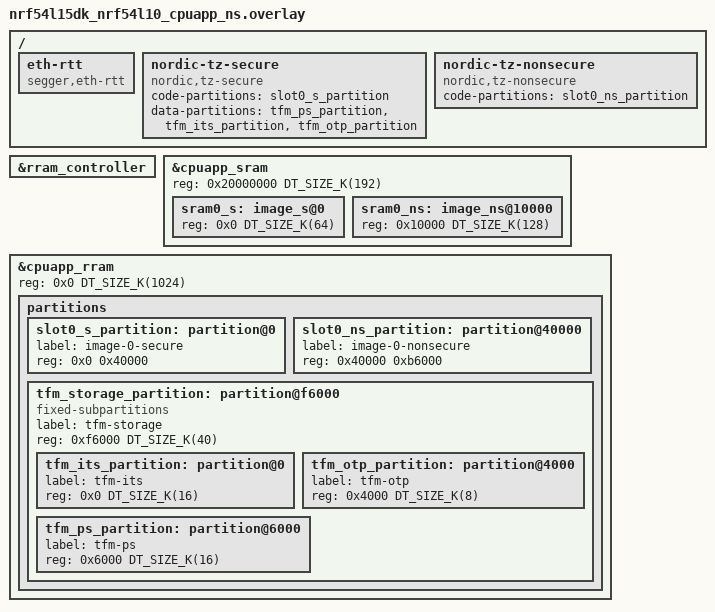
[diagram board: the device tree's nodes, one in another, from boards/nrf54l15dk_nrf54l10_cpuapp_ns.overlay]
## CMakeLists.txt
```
#
# Copyright (c) 2021 Nordic Semiconductor ASA
#
# SPDX-License-Identifier: LicenseRef-Nordic-5-Clause
#

cmake_minimum_required(VERSION 3.20.0)

find_package(Zephyr REQUIRED HINTS $ENV{ZEPHYR_BASE})

project(psa_tls_sample)

zephyr_include_directories(src ${COMMON_DIR})
target_include_directories(app PUBLIC ./include)
target_sources(app PRIVATE src/main.c
                           src/psa_tls_common.c)

if(CONFIG_BUILD_WITH_TFM)
  set(tls_src_path "non-secure")
else()
  set(tls_src_path "secure")
endif()

if(CONFIG_SAMPLE_PSA_TLS_TYPE_SERVER)
  target_sources(app PRIVATE src/${tls_src_path}/psa_tls_credentials_server.c)
  if(CONFIG_NET_SOCKETS_ENABLE_DTLS)
    target_sources(app PRIVATE src/psa_dtls_functions_server.c)
  else()
    target_sources(app PRIVATE src/psa_tls_functions_server.c)
  endif()
else()
  target_sources(app PRIVATE src/${tls_src_path}/psa_tls_credentials_client.c)
  if(CONFIG_NET_SOCKETS_ENABLE_DTLS)
    target_sources(app PRIVATE src/psa_dtls_functions_client.c)
  else()
    target_sources(app PRIVATE src/psa_tls_functions_client.c)
  endif()
endif()

set(gen_dir ${ZEPHYR_BINARY_DIR}/include/generated/)

if(CONFIG_SAMPLE_PSA_TLS_CERTIFICATE_TYPE_ECDSA)
  set(ctype "ec")
  if(CONFIG_PSA_WANT_ECC_SECP_R1_384)
    set(variant "-secp384r1")
  else()
    set(variant "-secp256r1")
  endif()
else()
  set(ctype "rsa")
  # This sample is configured to use RSA pkcs1v1.5 certificates for TLS 1.2,
  # and RSA-PSS certificates for TLS 1.3.
  if(CONFIG_MBEDTLS_SSL_PROTO_TLS1_3 AND CONFIG_PSA_WANT_ALG_RSA_PSS)
    set(variant "-pss")
  else()
    set(variant "-pkcs1v15")
  endif()
endif()

foreach(inc_file
  root-cert
  server-cert
  server-cert-key
)
  set(modified_inc_file "${ctype}-${inc_file}${variant}.der")
  generate_inc_file_for_target(
    app
    certs/${modified_inc_file}
    ${gen_dir}/${inc_file}.der.inc
  )
endforeach()
```

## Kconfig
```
#
# Copyright (c) 2021 Nordic Semiconductor
#
# SPDX-License-Identifier: LicenseRef-Nordic-5-Clause
#

source "Kconfig.zephyr"

menu "PSA TLS sample"

choice SAMPLE_PSA_TLS_CERTIFICATE_TYPE
	prompt "Certificate type"
	default SAMPLE_PSA_TLS_CERTIFICATE_TYPE_ECDSA
	help
	  Select the certificate type to use in the PSA TLS sample.

config SAMPLE_PSA_TLS_CERTIFICATE_TYPE_RSA
	bool "RSA certificate for the PSA TLS sample"
	help
	  Enable RSA certificates when testing ciphers that supports RSA for authentication.

config SAMPLE_PSA_TLS_CERTIFICATE_TYPE_ECDSA
	bool "ECDSA certificate for the PSA TLS sample"
	help
	  Enable ECDSA certificates when testing ciphers that supports ECDSA for authentication.

endchoice

choice SAMPLE_PSA_TLS_TYPE
	prompt "Server or client selection"
	default SAMPLE_PSA_TLS_TYPE_SERVER

config SAMPLE_PSA_TLS_TYPE_SERVER
	bool "Server functionality for the PSA TLS sample"
	help
	  When acting as a server, the sample waits for a connection from the client on port 4243.
	  After the TCP connection is established, the sample waits for the "ClientHello" message
	  from the client.

config SAMPLE_PSA_TLS_TYPE_CLIENT
	bool "Client functionality for the PSA TLS sample"
	help
	  When acting as a client, the sample tries to connect to the server on port 4243.
	  After the TCP connection is established, the sample automatically initiates the TLS handshake
	  by sending the "ClientHello" message.

endchoice

config SAMPLE_PSA_TLS_SERVER_PORT
	int "Server port number for the PSA TLS sample"
	range 1 65535
	default 4243
	help
	  The server port number for the PSA_TLS sample's network connection.

endmenu
```

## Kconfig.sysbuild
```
#
# Copyright (c) 2025 Nordic Semiconductor
#
# SPDX-License-Identifier: LicenseRef-Nordic-5-Clause
#

config PARTITION_MANAGER
	default n if SOC_SERIES_NRF53

source "share/sysbuild/Kconfig"
```

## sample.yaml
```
sample:
  description: |
    This sample demonstrates performing TLS handshake as either server or client.
  name: PSA TLS sample
common:
  sysbuild: true
  tags:
    - ci_build
    - sysbuild
    - ci_samples_crypto
  harness: console
  harness_config:
    type: multi_line
    ordered: true
    regex:
      - "Initializing network"
      - "psa_tls_sample: PSA TLS app started"
      - "psa_tls_credentials.* Registering"
      - "psa_tls_sample: Registering Pre-shared key"
      - "psa_.*(tls_client|tls_server).*TLS connection"
  timeout: 15
tests:
  ################################################################################
  ## ECDSA with Cryptocell and Oberon
  ################################################################################
  sample.psa_tls.tls_server.ecdsa.cc3xx_oberon:
    extra_args:
      EXTRA_CONF_FILE="overlays/server.conf;overlays/ecdsa_secp256r1.conf;overlays/tls_1_2_ecdsa.conf;overlays/cc3xx-oberon.conf"
    platform_allow: &cc3xx_oberon_platforms
      - nrf52840dk/nrf52840
      - nrf5340dk/nrf5340/cpuapp
      - nrf5340dk/nrf5340/cpuapp/ns
      - nrf9151dk/nrf9151
      - nrf9151dk/nrf9151/ns
    integration_platforms: &nrf5340_integration_platforms
      - nrf5340dk/nrf5340/cpuapp
      - nrf5340dk/nrf5340/cpuapp/ns
    tags:
      - cc3xx_oberon
  sample.psa_tls.dtls_server_secp384r1.ecdsa.cc3xx_oberon:
    extra_args:
      EXTRA_CONF_FILE="overlays/server.conf;overlays/ecdsa_secp384r1.conf;overlays/tls_1_2_ecdsa.conf;overlays/cc3xx-oberon.conf;overlays/dtls.conf"
    platform_allow: *cc3xx_oberon_platforms
    integration_platforms: &nrf9151_integration_platforms
      - nrf9151dk/nrf9151
      - nrf9151dk/nrf9151/ns
    tags:
      - dtls
      - cc3xx_oberon
      - secp384r1
  sample.psa_tls.tls_client.ecdsa.cc3xx_oberon:
    extra_args:
      EXTRA_CONF_FILE="overlays/client.conf;overlays/ecdsa_secp256r1.conf;overlays/tls_1_2_ecdsa.conf;overlays/cc3xx-oberon.conf"
    platform_allow: *cc3xx_oberon_platforms
    integration_platforms: &nrf52840_integration_platforms
      - nrf52840dk/nrf52840
    tags:
      - cc3xx_oberon
  sample.psa_tls.dtls_client_secp384r1.ecdsa.cc3xx_oberon:
    extra_args:
      EXTRA_CONF_FILE="overlays/client.conf;overlays/ecdsa_secp384r1.conf;overlays/tls_1_2_ecdsa.conf;overlays/cc3xx-oberon.conf;overlays/dtls.conf"
    platform_allow: *cc3xx_oberon_platforms
    integration_platforms: *nrf5340_integration_platforms
    tags:
      - dtls
      - cc3xx_oberon
      - secp384r1
  sample.psa_tls.tls_1_3_server.ecdsa.cc3xx_oberon:
    extra_args:
      EXTRA_CONF_FILE="overlays/server.conf;overlays/ecdsa_secp256r1.conf;overlays/tls_1_3_ecdsa.conf;overlays/cc3xx-oberon.conf"
    platform_allow: *cc3xx_oberon_platforms
    integration_platforms: *nrf5340_integration_platforms
    tags:
      - tls_1_3
      - cc3xx_oberon
  sample.psa_tls.tls_1_3_client.ecdsa.cc3xx_oberon:
    extra_args:
      EXTRA_CONF_FILE="overlays/client.conf;overlays/ecdsa_secp256r1.conf;overlays/tls_1_3_ecdsa.conf;overlays/cc3xx-oberon.conf"
    platform_allow: *cc3xx_oberon_platforms
    integration_platforms: *nrf9151_integration_platforms
    tags:
      - tls_1_3
      - cc3xx_oberon
  ################################################################################
  ## RSA with Cryptocell and Oberon
  ################################################################################
  sample.psa_tls.tls_server.rsa.cc3xx_oberon:
    extra_args:
      EXTRA_CONF_FILE="overlays/server.conf;overlays/tls_1_2_rsa.conf;overlays/cc3xx-oberon.conf"
    platform_allow: *cc3xx_oberon_platforms
    integration_platforms: *nrf5340_integration_platforms
    tags:
      - cc3xx_oberon
  sample.psa_tls.dtls_client.rsa.cc3xx_oberon:
    extra_args:
      EXTRA_CONF_FILE="overlays/client.conf;overlays/tls_1_2_rsa.conf;overlays/cc3xx-oberon.conf;overlays/dtls.conf"
    platform_allow: *cc3xx_oberon_platforms
    integration_platforms: *nrf9151_integration_platforms
    tags:
      - dtls
      - cc3xx_oberon
  sample.psa_tls.tls_1_3_server.rsa.cc3xx_oberon:
    extra_args:
      EXTRA_CONF_FILE="overlays/server.conf;overlays/tls_1_3_rsa.conf;overlays/cc3xx-oberon.conf"
    platform_allow: *cc3xx_oberon_platforms
    integration_platforms: *nrf9151_integration_platforms
    tags:
      - tls_1_3
      - cc3xx_oberon
  sample.psa_tls.tls_1_3_client.rsa.cc3xx_oberon:
    extra_args:
      EXTRA_CONF_FILE="overlays/client.conf;overlays/tls_1_3_rsa.conf;overlays/cc3xx-oberon.conf"
    platform_allow: *cc3xx_oberon_platforms
    integration_platforms: *nrf5340_integration_platforms
    tags:
      - tls_1_3
      - cc3xx_oberon
  ################################################################################
  ## ECDSA with Cracen
  ################################################################################
  sample.psa_tls.tls_server.ecdsa.cracen:
    extra_args:
      EXTRA_CONF_FILE="overlays/server.conf;overlays/ecdsa_secp256r1.conf;overlays/tls_1_2_ecdsa.conf;overlays/cracen.conf"
    platform_allow: &cracen_platforms
      - nrf54l15dk/nrf54l15/cpuapp
      - nrf54l15dk/nrf54l15/cpuapp/ns
      - nrf54lm20dk/nrf54lm20a/cpuapp
      - nrf54lm20dk/nrf54lm20a/cpuapp/ns
      - nrf54lm20dk/nrf54lm20b/cpuapp
      - nrf54lm20dk/nrf54lm20b/cpuapp/ns
      - nrf54lv10dk/nrf54lv10a/cpuapp
      - nrf54lv10dk/nrf54lv10a/cpuapp/ns
      - nrf54lc10dk/nrf54lc10a/cpuapp
      - nrf54lc10dk/nrf54lc10a/cpuapp/ns
      - nrf54l15dk/nrf54l10/cpuapp
      - nrf54l15dk/nrf54l10/cpuapp/ns
      - nrf7120dk/nrf7120/cpuapp
      - nrf7120dk/nrf7120/cpuapp/ns
    integration_platforms: &nrf54l15_integration_platforms
      - nrf54l15dk/nrf54l15/cpuapp
      - nrf54l15dk/nrf54l15/cpuapp/ns
    tags:
      - cracen
  sample.psa_tls.dtls_server.ecdsa.cracen:
    extra_args:
      EXTRA_CONF_FILE="overlays/server.conf;overlays/ecdsa_secp256r1.conf;overlays/tls_1_2_ecdsa.conf;overlays/cracen.conf;overlays/dtls.conf"
    platform_allow: *cracen_platforms
    integration_platforms: &nrf54lm20b_integration_platforms
      - nrf54lm20dk/nrf54lm20b/cpuapp
      - nrf54lm20dk/nrf54lm20b/cpuapp/ns
    tags:
      - dtls
      - cracen
  sample.psa_tls.tls_client.ecdsa.cracen:
    extra_args:
      EXTRA_CONF_FILE="overlays/client.conf;overlays/ecdsa_secp256r1.conf;overlays/tls_1_2_ecdsa.conf;overlays/cracen.conf"
    platform_allow: *cracen_platforms
    integration_platforms: &nrf54lv10a_integration_platforms
      - nrf54lv10dk/nrf54lv10a/cpuapp
      - nrf54lv10dk/nrf54lv10a/cpuapp/ns
    tags:
      - cracen
  sample.psa_tls.dtls_client.ecdsa.cracen:
    extra_args:
      EXTRA_CONF_FILE="overlays/client.conf;overlays/ecdsa_secp256r1.conf;overlays/tls_1_2_ecdsa.conf;overlays/cracen.conf;overlays/dtls.conf"
    platform_allow: *cracen_platforms
    integration_platforms: *nrf54l15_integration_platforms
    tags:
      - dtls
      - cracen
  sample.psa_tls.tls_server_secp384r1.ecdsa.cracen:
    extra_args:
      EXTRA_CONF_FILE="overlays/server.conf;overlays/ecdsa_secp384r1.conf;overlays/tls_1_2_ecdsa.conf;overlays/cracen.conf"
    platform_allow: *cracen_platforms
    integration_platforms: *nrf54lm20b_integration_platforms
    tags:
      - cracen
      - secp384r1
  sample.psa_tls.dtls_server_secp384r1.ecdsa.cracen:
    extra_args:
      EXTRA_CONF_FILE="overlays/server.conf;overlays/ecdsa_secp384r1.conf;overlays/tls_1_2_ecdsa.conf;overlays/cracen.conf;overlays/dtls.conf"
    platform_allow: *cracen_platforms
    integration_platforms: *nrf54lv10a_integration_platforms
    tags:
      - dtls
      - cracen
      - secp384r1
  sample.psa_tls.tls_client_secp384r1.ecdsa.cracen:
    extra_args:
      EXTRA_CONF_FILE="overlays/client.conf;overlays/ecdsa_secp384r1.conf;overlays/tls_1_2_ecdsa.conf;overlays/cracen.conf"
    platform_allow: *cracen_platforms
    integration_platforms: *nrf54lm20b_integration_platforms
    tags:
      - cracen
      - secp384r1
  sample.psa_tls.dtls_client_secp384r1.ecdsa.cracen:
    extra_args:
      EXTRA_CONF_FILE="overlays/client.conf;overlays/ecdsa_secp384r1.conf;overlays/tls_1_2_ecdsa.conf;overlays/cracen.conf;overlays/dtls.conf"
    platform_allow: *cracen_platforms
    integration_platforms: *nrf54l15_integration_platforms
    tags:
      - dtls
      - cracen
      - secp384r1
  sample.psa_tls.tls_1_3_server.ecdsa.cracen:
    extra_args:
      EXTRA_CONF_FILE="overlays/server.conf;overlays/ecdsa_secp256r1.conf;overlays/tls_1_3_ecdsa.conf;overlays/cracen.conf"
    platform_allow: *cracen_platforms
    integration_platforms: *nrf54lv10a_integration_platforms
    tags:
      - tls_1_3
      - cracen
  sample.psa_tls.tls_1_3_client.ecdsa.cracen:
    extra_args:
      EXTRA_CONF_FILE="overlays/client.conf;overlays/ecdsa_secp256r1.conf;overlays/tls_1_3_ecdsa.conf;overlays/cracen.conf"
    platform_allow: *cracen_platforms
    integration_platforms: *nrf54lm20b_integration_platforms
    tags:
      - tls_1_3
      - cracen
  ################################################################################
  ## ECDSA with Cracen crypto service
  ################################################################################
  sample.psa_tls.tls_server.ecdsa.cracen.crypto_service:
    extra_args:
      EXTRA_CONF_FILE="overlays/server.conf;overlays/ecdsa_secp256r1.conf;overlays/tls_1_2_ecdsa.conf;overlays/cracen.conf"
    platform_allow: &nrf54h20_cracen_platforms
      - nrf54h20dk/nrf54h20/cpuapp
      - nrf54h20dk/nrf54h20/cpurad
    integration_platforms:
      - nrf54h20dk/nrf54h20/cpuapp
    tags:
      - cracen
  sample.psa_tls.dtls_server.ecdsa.cracen.crypto_service:
    extra_args:
      EXTRA_CONF_FILE="overlays/server.conf;overlays/ecdsa_secp256r1.conf;overlays/tls_1_2_ecdsa.conf;overlays/cracen.conf;overlays/dtls.conf"
    platform_allow: *nrf54h20_cracen_platforms
    integration_platforms:
      - nrf54h20dk/nrf54h20/cpurad
    tags:
      - dtls
      - cracen
  sample.psa_tls.tls_client.ecdsa.cracen.crypto_service:
    extra_args:
      EXTRA_CONF_FILE="overlays/client.conf;overlays/ecdsa_secp256r1.conf;overlays/tls_1_2_ecdsa.conf;overlays/cracen.conf"
    platform_allow: *nrf54h20_cracen_platforms
    integration_platforms:
      - nrf54h20dk/nrf54h20/cpurad
    tags:
      - cracen
  sample.psa_tls.dtls_client.ecdsa.cracen.crypto_service:
    extra_args:
      EXTRA_CONF_FILE="overlays/client.conf;overlays/ecdsa_secp256r1.conf;overlays/tls_1_2_ecdsa.conf;overlays/cracen.conf;overlays/dtls.conf"
    platform_allow: *nrf54h20_cracen_platforms
    integration_platforms:
      - nrf54h20dk/nrf54h20/cpuapp
    tags:
      - dtls
      - cracen
  sample.psa_tls.tls_server_secp384r1.ecdsa.cracen.crypto_service:
    extra_args:
      EXTRA_CONF_FILE="overlays/server.conf;overlays/ecdsa_secp384r1.conf;overlays/tls_1_2_ecdsa.conf;overlays/cracen.conf"
    platform_allow: *nrf54h20_cracen_platforms
    integration_platforms:
      - nrf54h20dk/nrf54h20/cpurad
    tags:
      - cracen
      - secp384r1
  sample.psa_tls.dtls_server_secp384r1.ecdsa.cracen.crypto_service:
    extra_args:
      EXTRA_CONF_FILE="overlays/server.conf;overlays/ecdsa_secp384r1.conf;overlays/tls_1_2_ecdsa.conf;overlays/cracen.conf;overlays/dtls.conf"
    platform_allow: *nrf54h20_cracen_platforms
    integration_platforms:
      - nrf54h20dk/nrf54h20/cpuapp
    tags:
      - dtls
      - cracen
      - secp384r1
  sample.psa_tls.tls_client_secp384r1.ecdsa.cracen.crypto_service:
    extra_args:
      EXTRA_CONF_FILE="overlays/client.conf;overlays/ecdsa_secp384r1.conf;overlays/tls_1_2_ecdsa.conf;overlays/cracen.conf"
    platform_allow: *nrf54h20_cracen_platforms
    integration_platforms:
      - nrf54h20dk/nrf54h20/cpuapp
    tags:
      - cracen
      - secp384r1
  sample.psa_tls.dtls_client_secp384r1.ecdsa.cracen.crypto_service:
    extra_args:
      EXTRA_CONF_FILE="overlays/client.conf;overlays/ecdsa_secp384r1.conf;overlays/tls_1_2_ecdsa.conf;overlays/cracen.conf;overlays/dtls.conf"
    platform_allow: *nrf54h20_cracen_platforms
    integration_platforms:
      - nrf54h20dk/nrf54h20/cpurad
    tags:
      - dtls
      - cracen
      - secp384r1
  sample.psa_tls.tls_1_3_server.ecdsa.cracen.crypto_service:
    extra_args:
      EXTRA_CONF_FILE="overlays/server.conf;overlays/ecdsa_secp256r1.conf;overlays/tls_1_3_ecdsa.conf;overlays/cracen.conf"
    platform_allow: *nrf54h20_cracen_platforms
    integration_platforms:
      - nrf54h20dk/nrf54h20/cpuapp
    tags:
      - tls_1_3
      - cracen
  sample.psa_tls.tls_1_3_client.ecdsa.cracen.crypto_service:
    extra_args:
      EXTRA_CONF_FILE="overlays/client.conf;overlays/ecdsa_secp256r1.conf;overlays/tls_1_3_ecdsa.conf;overlays/cracen.conf"
    platform_allow: *nrf54h20_cracen_platforms
    integration_platforms:
      - nrf54h20dk/nrf54h20/cpurad
    tags:
      - tls_1_3
      - cracen
  ################################################################################
  ## RSA with Cracen
  ################################################################################
  sample.psa_tls.tls_server.rsa.cracen:
    extra_args:
      EXTRA_CONF_FILE="overlays/server.conf;overlays/tls_1_2_rsa.conf;overlays/cracen.conf"
    platform_allow: *cracen_platforms
    integration_platforms: *nrf54lv10a_integration_platforms
    tags:
      - cracen
  sample.psa_tls.dtls_server.rsa.cracen:
    extra_args:
      EXTRA_CONF_FILE="overlays/server.conf;overlays/tls_1_2_rsa.conf;overlays/cracen.conf;overlays/dtls.conf"
    platform_allow: *cracen_platforms
    integration_platforms: *nrf54l15_integration_platforms
    tags:
      - dtls
      - cracen
  sample.psa_tls.tls_client.rsa.cracen:
    extra_args:
      EXTRA_CONF_FILE="overlays/client.conf;overlays/tls_1_2_rsa.conf;overlays/cracen.conf"
    platform_allow: *cracen_platforms
    integration_platforms: *nrf54lm20b_integration_platforms
    tags:
      - cracen
  sample.psa_tls.dtls_client.rsa.cracen:
    extra_args:
      EXTRA_CONF_FILE="overlays/client.conf;overlays/tls_1_2_rsa.conf;overlays/cracen.conf;overlays/dtls.conf"
    platform_allow: *cracen_platforms
    integration_platforms: *nrf54l15_integration_platforms
    tags:
      - dtls
      - cracen
  sample.psa_tls.tls_1_3_server.rsa.cracen:
    extra_args:
      EXTRA_CONF_FILE="overlays/server.conf;overlays/tls_1_3_rsa.conf;overlays/cracen.conf"
    platform_allow: *cracen_platforms
    integration_platforms: *nrf54lm20b_integration_platforms
    tags:
      - tls_1_3
      - cracen
  sample.psa_tls.tls_1_3_client.rsa.cracen:
    extra_args:
      EXTRA_CONF_FILE="overlays/client.conf;overlays/tls_1_3_rsa.conf;overlays/cracen.conf"
    platform_allow: *cracen_platforms
    integration_platforms: &nrf54lc10a_integration_platforms
      - nrf54lc10dk/nrf54lc10a/cpuapp
      - nrf54lc10dk/nrf54lc10a/cpuapp/ns
    tags:
      - tls_1_3
      - cracen
  ################################################################################
  ## ECDSA with Oberon
  ################################################################################
  sample.psa_tls.tls_server.ecdsa.oberon:
    extra_args:
      EXTRA_CONF_FILE="overlays/server.conf;overlays/ecdsa_secp256r1.conf;overlays/tls_1_2_ecdsa.conf;overlays/oberon.conf"
    platform_allow: &nrf54ls05_oberon_platforms
      - nrf54ls05dk/nrf54ls05b/cpuapp
    integration_platforms: *nrf54ls05_oberon_platforms
    tags:
      - oberon
  sample.psa_tls.dtls_server.ecdsa.oberon:
    extra_args:
      EXTRA_CONF_FILE="overlays/server.conf;overlays/ecdsa_secp256r1.conf;overlays/tls_1_2_ecdsa.conf;overlays/oberon.conf;overlays/dtls.conf"
    platform_allow: *nrf54ls05_oberon_platforms
    integration_platforms: *nrf54ls05_oberon_platforms
    tags:
      - dtls
      - oberon
  sample.psa_tls.tls_client.ecdsa.oberon:
    extra_args:
      EXTRA_CONF_FILE="overlays/client.conf;overlays/ecdsa_secp256r1.conf;overlays/tls_1_2_ecdsa.conf;overlays/oberon.conf"
    platform_allow: *nrf54ls05_oberon_platforms
    integration_platforms: *nrf54ls05_oberon_platforms
    tags:
      - oberon
  sample.psa_tls.dtls_client.ecdsa.oberon:
    extra_args:
      EXTRA_CONF_FILE="overlays/client.conf;overlays/ecdsa_secp256r1.conf;overlays/tls_1_2_ecdsa.conf;overlays/oberon.conf;overlays/dtls.conf"
    platform_allow: *nrf54ls05_oberon_platforms
    integration_platforms: *nrf54ls05_oberon_platforms
    tags:
      - dtls
      - oberon
  sample.psa_tls.tls_server_secp384r1.ecdsa.oberon:
    extra_args:
      EXTRA_CONF_FILE="overlays/server.conf;overlays/ecdsa_secp384r1.conf;overlays/tls_1_2_ecdsa.conf;overlays/oberon.conf"
    platform_allow: *nrf54ls05_oberon_platforms
    integration_platforms: *nrf54ls05_oberon_platforms
    tags:
      - oberon
      - secp384r1
  sample.psa_tls.dtls_server_secp384r1.ecdsa.oberon:
    extra_args:
      EXTRA_CONF_FILE="overlays/server.conf;overlays/ecdsa_secp384r1.conf;overlays/tls_1_2_ecdsa.conf;overlays/oberon.conf;overlays/dtls.conf"
    platform_allow: *nrf54ls05_oberon_platforms
    integration_platforms: *nrf54ls05_oberon_platforms
    tags:
      - dtls
      - oberon
      - secp384r1
  sample.psa_tls.tls_client_secp384r1.ecdsa.oberon:
    extra_args:
      EXTRA_CONF_FILE="overlays/client.conf;overlays/ecdsa_secp384r1.conf;overlays/tls_1_2_ecdsa.conf;overlays/oberon.conf"
    platform_allow: *nrf54ls05_oberon_platforms
    integration_platforms: *nrf54ls05_oberon_platforms
    tags:
      - oberon
      - secp384r1
  sample.psa_tls.dtls_client_secp384r1.ecdsa.oberon:
    extra_args:
      EXTRA_CONF_FILE="overlays/client.conf;overlays/ecdsa_secp384r1.conf;overlays/tls_1_2_ecdsa.conf;overlays/oberon.conf;overlays/dtls.conf"
    platform_allow: *nrf54ls05_oberon_platforms
    integration_platforms: *nrf54ls05_oberon_platforms
    tags:
      - dtls
      - oberon
      - secp384r1
  sample.psa_tls.tls_1_3_server.ecdsa.oberon:
    extra_args:
      EXTRA_CONF_FILE="overlays/server.conf;overlays/ecdsa_secp256r1.conf;overlays/tls_1_3_ecdsa.conf;overlays/oberon.conf"
    platform_allow: *nrf54ls05_oberon_platforms
    integration_platforms: *nrf54ls05_oberon_platforms
    tags:
      - tls_1_3
      - oberon
  sample.psa_tls.tls_1_3_client.ecdsa.oberon:
    extra_args:
      EXTRA_CONF_FILE="overlays/client.conf;overlays/ecdsa_secp256r1.conf;overlays/tls_1_3_ecdsa.conf;overlays/oberon.conf"
    platform_allow: *nrf54ls05_oberon_platforms
    integration_platforms: *nrf54ls05_oberon_platforms
    tags:
      - tls_1_3
      - oberon
  ################################################################################
  ## RSA with Oberon
  ################################################################################
  sample.psa_tls.tls_server.rsa.oberon:
    extra_args:
      EXTRA_CONF_FILE="overlays/server.conf;overlays/tls_1_2_rsa.conf;overlays/oberon.conf"
    platform_allow: *nrf54ls05_oberon_platforms
    integration_platforms: *nrf54ls05_oberon_platforms
    tags:
      - oberon
  sample.psa_tls.dtls_server.rsa.oberon:
    extra_args:
      EXTRA_CONF_FILE="overlays/server.conf;overlays/tls_1_2_rsa.conf;overlays/oberon.conf;overlays/dtls.conf"
    platform_allow: *nrf54ls05_oberon_platforms
    integration_platforms: *nrf54ls05_oberon_platforms
    tags:
      - dtls
      - oberon
  sample.psa_tls.tls_client.rsa.oberon:
    extra_args:
      EXTRA_CONF_FILE="overlays/client.conf;overlays/tls_1_2_rsa.conf;overlays/oberon.conf"
    platform_allow: *nrf54ls05_oberon_platforms
    integration_platforms: *nrf54ls05_oberon_platforms
    tags:
      - oberon
  sample.psa_tls.dtls_client.rsa.oberon:
    extra_args:
      EXTRA_CONF_FILE="overlays/client.conf;overlays/tls_1_2_rsa.conf;overlays/oberon.conf;overlays/dtls.conf"
    platform_allow: *nrf54ls05_oberon_platforms
    integration_platforms: *nrf54ls05_oberon_platforms
    tags:
      - dtls
      - oberon
  sample.psa_tls.tls_1_3_server.rsa.oberon:
    extra_args:
      EXTRA_CONF_FILE="overlays/server.conf;overlays/tls_1_3_rsa.conf;overlays/oberon.conf"
    platform_allow: *nrf54ls05_oberon_platforms
    integration_platforms: *nrf54ls05_oberon_platforms
    tags:
      - tls_1_3
      - oberon
  sample.psa_tls.tls_1_3_client.rsa.oberon:
    extra_args:
      EXTRA_CONF_FILE="overlays/client.conf;overlays/tls_1_3_rsa.conf;overlays/oberon.conf"
    platform_allow: *nrf54ls05_oberon_platforms
    integration_platforms: *nrf54ls05_oberon_platforms
    tags:
      - tls_1_3
      - oberon
```

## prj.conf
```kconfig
#
# Copyright (c) 2021 Nordic Semiconductor ASA
#
# SPDX-License-Identifier: LicenseRef-Nordic-5-Clause
#

# Configure main thread
CONFIG_MAIN_STACK_SIZE=8192

# Configure logging
CONFIG_LOG=y
CONFIG_PRINTK=y
CONFIG_NET_LOG=y
CONFIG_LOG_DEFAULT_LEVEL=3
CONFIG_LOG_MODE_IMMEDIATE=y
CONFIG_LOG_ALWAYS_RUNTIME=y

# Configure networking
CONFIG_NETWORKING=y
CONFIG_NET_UDP=n
CONFIG_NET_TCP=y
CONFIG_NET_IPV6=n
CONFIG_NET_IPV4=y
CONFIG_NET_SOCKETS=y
CONFIG_NET_TCP_ISN_RFC6528=n
CONFIG_NET_CONFIG_SETTINGS=y
CONFIG_NET_CONFIG_NEED_IPV6=n
CONFIG_NET_CONFIG_NEED_IPV4=y
CONFIG_POSIX_API=y
CONFIG_NET_CONNECTION_MANAGER=n
CONFIG_NET_CONTEXT_NET_PKT_POOL=y

# Configure TLS networking
CONFIG_NET_SOCKETS_SOCKOPT_TLS=y
CONFIG_NET_SOCKETS_ENABLE_DTLS=n
CONFIG_NET_SOCKETS_TLS_MAX_CONTEXTS=6
CONFIG_NET_SOCKETS_TLS_MAX_CIPHERSUITES=16

# Configure network buffers
CONFIG_NET_MAX_CONTEXTS=6
CONFIG_NET_PKT_RX_COUNT=16
CONFIG_NET_PKT_TX_COUNT=16
CONFIG_NET_BUF_RX_COUNT=100
CONFIG_NET_BUF_TX_COUNT=100

# Configure Mbed TLS and security
CONFIG_MBEDTLS_PK_C=y

CONFIG_MBEDTLS_ENABLE_HEAP=y
CONFIG_MBEDTLS_HEAP_SIZE=32768
CONFIG_MBEDTLS_SSL_IN_CONTENT_LEN=2304
CONFIG_MBEDTLS_SSL_OUT_CONTENT_LEN=2304
CONFIG_MBEDTLS_SSL_CLI_C=y
CONFIG_MBEDTLS_SSL_CACHE_C=y

CONFIG_PSA_WANT_GENERATE_RANDOM=y

# Enable RTT ethernet driver
CONFIG_ETH_RTT=y

# Enable optimizations
CONFIG_SPEED_OPTIMIZATIONS=y
```

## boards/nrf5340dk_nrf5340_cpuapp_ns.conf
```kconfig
#
# Copyright (c) 2024 Nordic Semiconductor ASA
#
# SPDX-License-Identifier: LicenseRef-Nordic-5-Clause
#
CONFIG_NRF_ENABLE_ICACHE=n
CONFIG_MBEDTLS_PSA_CRYPTO_C=n
```

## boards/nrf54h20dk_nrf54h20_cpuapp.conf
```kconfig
#
# Copyright (c) 2024 Nordic Semiconductor
#
# SPDX-License-Identifier: LicenseRef-Nordic-5-Clause
#

# Disable Oberon PSA crypto drivers
CONFIG_PSA_CRYPTO_DRIVER_OBERON=n

# Enable PSA crypto from SSF client
CONFIG_NRF_IRONSIDE_SE_PSA_SERVICES=y
```

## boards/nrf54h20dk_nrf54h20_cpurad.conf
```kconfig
#
# Copyright (c) 2024 Nordic Semiconductor
#
# SPDX-License-Identifier: LicenseRef-Nordic-5-Clause
#

# Disable Oberon PSA crypto drivers
CONFIG_PSA_CRYPTO_DRIVER_OBERON=n

# Enable PSA crypto from SSF client
CONFIG_PSA_SSF_CRYPTO_CLIENT=y
CONFIG_SSF_PSA_CRYPTO_SERVICE_ENABLED=y
```

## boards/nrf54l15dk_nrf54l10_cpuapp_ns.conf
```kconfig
#
# Copyright (c) 2025 Nordic Semiconductor ASA
#
# SPDX-License-Identifier: LicenseRef-Nordic-5-Clause
#
CONFIG_NRF_ENABLE_ICACHE=n
CONFIG_MBEDTLS_PSA_CRYPTO_C=y

# The ECDSA CA certificate is stored persistently with Protected Storage,
# which internally uses Internal Trusted Storage. Since ITS encryption is
# enabled by default for nRF54L10, the sample must be configured with a
# larger ITS asset size than the default 500 bytes. This is because
# encrypted ITS assets must be stored in a single chunk.
CONFIG_TFM_ITS_MAX_ASSET_SIZE_OVERRIDE=y
CONFIG_TFM_ITS_MAX_ASSET_SIZE=600
```

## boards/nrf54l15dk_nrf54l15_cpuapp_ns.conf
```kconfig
#
# Copyright (c) 2024 Nordic Semiconductor ASA
#
# SPDX-License-Identifier: LicenseRef-Nordic-5-Clause
#
CONFIG_NRF_ENABLE_ICACHE=n
CONFIG_MBEDTLS_PSA_CRYPTO_C=n

# The ECDSA CA certificate is stored persistently with Protected Storage,
# which internally uses Internal Trusted Storage. Since ITS encryption is
# enabled by default for nRF54L15, the sample must be configured with a
# larger ITS asset size than the default 500 bytes. This is because
# encrypted ITS assets must be stored in a single chunk.
CONFIG_TFM_ITS_MAX_ASSET_SIZE_OVERRIDE=y
CONFIG_TFM_ITS_MAX_ASSET_SIZE=600
```

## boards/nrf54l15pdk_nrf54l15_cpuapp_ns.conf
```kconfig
#
# Copyright (c) 2024 Nordic Semiconductor ASA
#
# SPDX-License-Identifier: LicenseRef-Nordic-5-Clause
#
CONFIG_TFM_PROFILE_TYPE_NOT_SET=y
CONFIG_NRF_ENABLE_ICACHE=n
CONFIG_MBEDTLS_USE_PSA_CRYPTO=y
CONFIG_MBEDTLS_PSA_CRYPTO_C=y

# The ECDSA CA certificate is stored persistently with Protected Storage,
# which internally uses Internal Trusted Storage. Since ITS encryption is
# enabled by default for nRF54L20, the sample must be configured with a
# larger ITS asset size than the default 500 bytes. This is because
# encrypted ITS assets must be stored in a single chunk.
CONFIG_TFM_ITS_MAX_ASSET_SIZE_OVERRIDE=y
CONFIG_TFM_ITS_MAX_ASSET_SIZE=600
```

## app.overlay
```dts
/*
 * Copyright (c) 2021 Nordic Semiconductor ASA
 *
 * SPDX-License-Identifier: LicenseRef-Nordic-5-Clause
 */

/ {
	eth-rtt {
		compatible = "segger,eth-rtt";
	};
};
```

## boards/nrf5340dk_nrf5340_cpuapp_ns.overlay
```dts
/delete-node/ &boot_partition;
/delete-node/ &slot0_partition;
/delete-node/ &slot1_partition;
/delete-node/ &storage_partition;

/delete-node/ &tfm_its_partition;
/delete-node/ &tfm_otp_partition;
/delete-node/ &tfm_ps_partition;

/ {
	eth-rtt {
		compatible = "segger,eth-rtt";
	};
};

&flash0 {
	partitions {
		slot0_s_partition: partition@0 {
			compatible = "zephyr,mapped-partition";
			label = "image-0-secure";
			reg = <0x0 0x60000>;
		};

		slot0_ns_partition: partition@60000 {
			compatible = "zephyr,mapped-partition";
			label = "image-0-nonsecure";
			reg = <0x60000 0x98000>;
		};

		tfm_storage_partition: partition@f8000 {
			compatible = "zephyr,mapped-partition";
			label = "tfm-storage";
			reg = <0xf8000 DT_SIZE_K(32)>;
			ranges = <0x0 0xf8000 DT_SIZE_K(32)>;
			#address-cells = <1>;
			#size-cells = <1>;

			tfm_its_partition: partition@0 {
				compatible = "zephyr,mapped-partition";
				label = "tfm-its";
				reg = <0x0 DT_SIZE_K(8)>;
			};

			tfm_otp_partition: partition@2000 {
				compatible = "zephyr,mapped-partition";
				label = "tfm-otp";
				reg = <0x2000 DT_SIZE_K(8)>;
			};

			tfm_ps_partition: partition@4000 {
				compatible = "zephyr,mapped-partition";
				label = "tfm-ps";
				reg = <0x4000 DT_SIZE_K(16)>;
			};
		};
	};
};

/ {
	/delete-node/ nordic-tz-secure;
	/delete-node/ nordic-tz-nonsecure;

	nordic-tz-secure {
		compatible = "nordic,tz-secure";
		code-partitions = <&slot0_s_partition>;
		data-partitions = <&tfm_ps_partition>,
				  <&tfm_its_partition>,
				  <&tfm_otp_partition>;
	};

	nordic-tz-nonsecure {
		compatible = "nordic,tz-nonsecure";
		code-partitions = <&slot0_ns_partition>;
	};
};
```

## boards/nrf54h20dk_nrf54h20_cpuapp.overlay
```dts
/*
 * Copyright (c) 2024 Nordic Semiconductor ASA
 *
 * SPDX-License-Identifier: LicenseRef-Nordic-5-Clause
 */

/ {
	eth-rtt {
		compatible = "segger,eth-rtt";
	};
};
```

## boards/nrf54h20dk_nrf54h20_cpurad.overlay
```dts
/*
 * Copyright (c) 2024 Nordic Semiconductor ASA
 *
 * SPDX-License-Identifier: LicenseRef-Nordic-5-Clause
 */
/ {
	eth-rtt {
		compatible = "segger,eth-rtt";
	};
};
```

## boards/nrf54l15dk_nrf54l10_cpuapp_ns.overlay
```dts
/*
 * Copyright (c) 2026 Nordic Semiconductor
 *
 * SPDX-License-Identifier: LicenseRef-Nordic-5-Clause
 */

/delete-node/ &slot0_partition;
/delete-node/ &slot0_ns_partition;
/delete-node/ &storage_partition;

/delete-node/ &tfm_its_partition;
/delete-node/ &tfm_otp_partition;
/delete-node/ &tfm_ps_partition;

/delete-node/ &sram0_s;
/delete-node/ &sram0_ns;

&rram_controller {
	/delete-node/ cpuflpr_sram;
	/delete-node/ cpuflpr_rram;
};

/* Adjust cpuapp_sram to include the freed-up cpuflpr_sram (192 kB total)
 * and rebalance the secure/non-secure split to 64 kB / 128 kB so the
 * non-secure image (psa_tls needs ~115 kB of RAM) fits.
 */
&cpuapp_sram {
	reg = <0x20000000 DT_SIZE_K(192)>;
	ranges = <0x0 0x20000000 0x20030000>;

	sram0_s: image_s@0 {
		#address-cells = <1>;
		#size-cells = <1>;
		/* Secure image memory */
		reg = <0x0 DT_SIZE_K(64)>;
		ranges = <0x0 0x0 DT_SIZE_K(64)>;
	};

	sram0_ns: image_ns@10000 {
		#address-cells = <1>;
		#size-cells = <1>;
		/* Non-Secure image memory */
		reg = <0x10000 DT_SIZE_K(128)>;
		ranges = <0x0 0x10000 DT_SIZE_K(128)>;
	};
};

/* Adjust cpuapp_rram to include the freed-up cpuflpr_rram */
&cpuapp_rram {
	reg = <0x0 DT_SIZE_K(1024)>;

	partitions {
		slot0_s_partition: partition@0 {
			label = "image-0-secure";
			reg = <0x0 0x40000>;
		};

		slot0_ns_partition: partition@40000 {
			label = "image-0-nonsecure";
			reg = <0x40000 0xb6000>;
		};

		tfm_storage_partition: partition@f6000 {
			compatible = "fixed-subpartitions";
			label = "tfm-storage";
			reg = <0xf6000 DT_SIZE_K(40)>;
			ranges = <0x0 0xf6000 DT_SIZE_K(40)>;
			#address-cells = <1>;
			#size-cells = <1>;

			tfm_its_partition: partition@0 {
				label = "tfm-its";
				reg = <0x0 DT_SIZE_K(16)>;
			};

			tfm_otp_partition: partition@4000 {
				label = "tfm-otp";
				reg = <0x4000 DT_SIZE_K(8)>;
			};

			tfm_ps_partition: partition@6000 {
				label = "tfm-ps";
				reg = <0x6000 DT_SIZE_K(16)>;
			};
		};
	};
};

/ {
	eth-rtt {
		compatible = "segger,eth-rtt";
	};
};

/ {
	/delete-node/ nordic-tz-secure;
	/delete-node/ nordic-tz-nonsecure;

	nordic-tz-secure {
		compatible = "nordic,tz-secure";
		code-partitions = <&slot0_s_partition>;
		data-partitions = <&tfm_ps_partition>,
				  <&tfm_its_partition>,
				  <&tfm_otp_partition>;
	};

	nordic-tz-nonsecure {
		compatible = "nordic,tz-nonsecure";
		code-partitions = <&slot0_ns_partition>;
	};
};
```

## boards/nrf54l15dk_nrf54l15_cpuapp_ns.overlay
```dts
/*
 * Copyright (c) 2026 Nordic Semiconductor
 *
 * SPDX-License-Identifier: LicenseRef-Nordic-5-Clause
 */

/* Adjust the cpuapp_sram to include the freed up cpuflpr_sram */
&cpuapp_sram {
	reg = <0x20000000 DT_SIZE_K(256)>;
	ranges = <0x0 0x20000000 0x20040000>;
};

/* Adjust the cpuapp_rram to include the freed up cpuflpr_rram */
&cpuapp_rram {
	reg = <0x0 DT_SIZE_K(1536)>;
};

/ {
	eth-rtt {
		compatible = "segger,eth-rtt";
	};
};
```

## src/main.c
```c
/*
 * Copyright (c) 2021 Nordic Semiconductor ASA.
 *
 * SPDX-License-Identifier: LicenseRef-Nordic-5-Clause
 */

#include <zephyr/logging/log.h>
#include <zephyr/net/tls_credentials.h>

#include <psa/crypto.h>

#include <psa_tls_functions.h>
#include <psa_tls_credentials.h>
#include <certificate.h>
#include <dummy_psk.h>

LOG_MODULE_REGISTER(psa_tls_sample);

static int tls_set_preshared_key(void)
{
	LOG_INF("Registering Pre-shared key");

	int err = tls_credential_add(PSK_TAG, TLS_CREDENTIAL_PSK,
				     psk, sizeof(psk));
	if (err < 0) {
		LOG_ERR("Failed to register PSK: %d", err);
		return err;
	}
	err = tls_credential_add(PSK_TAG, TLS_CREDENTIAL_PSK_ID,
				 psk_id, strlen(psk_id));
	if (err < 0) {
		LOG_ERR("Failed to register PSK ID: %d", err);
		return err;
	}

	return APP_SUCCESS;
}

int main(void)
{
	int err;

	LOG_INF("PSA TLS app started");

	err = psa_crypto_init();
	if (err < 0) {
		return APP_ERROR;
	}

	err = tls_set_credentials();
	if (err < 0) {
		return APP_ERROR;
	}

	err = tls_set_preshared_key();
	if (err < 0) {
		return APP_ERROR;
	}

	process_psa_tls();

	return APP_SUCCESS;
}
```

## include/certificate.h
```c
/*
 * Copyright (c) 2021 Nordic Semiconductor ASA.
 *
 * SPDX-License-Identifier: LicenseRef-Nordic-5-Clause
 */

#ifndef __CERTIFICATE_H__
#define __CERTIFICATE_H__

#define CA_CERTIFICATE_TAG 1
#define SERVER_CERTIFICATE_TAG 2
#define PSK_TAG 3

static const unsigned char ca_certificate[] = {
#include <root-cert.der.inc>
};
static const unsigned char server_certificate[] = {
#include <server-cert.der.inc>
};
/* This is the private key in pkcs#8 format. */
static const unsigned char private_key[] = {
#include <server-cert-key.der.inc>
};

#endif /* __CERTIFICATE_H__ */
```

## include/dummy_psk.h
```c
/*
 * Copyright (c) 2021 Nordic Semiconductor ASA.
 *
 * SPDX-License-Identifier: LicenseRef-Nordic-5-Clause
 */

#ifndef __DUMMY_PSK_H__
#define __DUMMY_PSK_H__

static const unsigned char psk[] = {0x01, 0x01, 0x02, 0x03, 0x04, 0x05, 0x06,
0x07, 0x08, 0x09, 0x0a, 0x0b, 0x0c, 0x0d, 0x0e, 0x0f};
static const char psk_id[] = "PSK_identity";

#endif /* __DUMMY_PSK_H__ */
```

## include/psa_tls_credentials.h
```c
/*
 * Copyright (c) 2021 Nordic Semiconductor ASA.
 *
 * SPDX-License-Identifier: LicenseRef-Nordic-5-Clause
 */

#ifndef TLS_CREDENTIALS_H__
#define TLS_CREDENTIALS_H__

#ifdef __cplusplus
extern "C" {
#endif


#define PSA_PS_CERTIFICATE_UID		(1)
#define PSA_PS_CERTIFICATE_KEY_UID	(2)
#define PSA_PS_CA_CERTIFICATE_UID	(3)

#define APP_SUCCESS			(0)
#define APP_ERROR			(-1)


/** @brief Function for registering certificates and PSKs.
 *
 * @retval 0 TLS credential successfully set.
 */
int tls_set_credentials(void);


#ifdef __cplusplus
}
#endif

#endif /* TLS_CREDENTIALS_H__ */
```

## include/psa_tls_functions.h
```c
/*
 * Copyright (c) 2021 Nordic Semiconductor ASA.
 *
 * SPDX-License-Identifier: LicenseRef-Nordic-5-Clause
 */

#ifndef TLS_FUNCTIONS_H__
#define TLS_FUNCTIONS_H__

#ifdef __cplusplus
extern "C" {
#endif


#define RECV_BUFFER_SIZE 2400		/* Receive-buffer size in bytes. */
#define MAX_CLIENT_QUEUE 1		/* Max number of connections in listen queue. */
#define TLS_PEER_HOSTNAME "localhost"	/* Peer TLS hostname when functioning as client. */


/** @brief Function for starting a TLS or a DTLS thread.
 *
 */
void process_psa_tls(void);

/** @brief Function for starting a TLS or a DTLS thread.
 *
 */
int psa_tls_send_buffer(int sock, const uint8_t *buf, size_t len);


#ifdef __cplusplus
}
#endif

#endif /* TLS_FUNCTIONS_H__ */
```

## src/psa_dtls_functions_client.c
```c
/*
 * Copyright (c) 2023 Nordic Semiconductor ASA.
 *
 * SPDX-License-Identifier: LicenseRef-Nordic-5-Clause
 */

#include <arpa/inet.h>
#include <errno.h>
#include <sys/socket.h>
#include <unistd.h>

#include <zephyr/logging/log.h>
#include <zephyr/net/tls_credentials.h>

#include <certificate.h>
#include <psa_tls_functions.h>
#include <psa_tls_credentials.h>

LOG_MODULE_REGISTER(psa_dtls_client);

static char recv_buffer[RECV_BUFFER_SIZE]; /* Buffer for storing payload */

/** @brief Function for setting up the client socket to use for DTLS handshake.
 *
 * @returns The socket identifier.
 */
static int setup_dtls_client_socket(void)
{
	int err;
	int sock;
	int verify = TLS_PEER_VERIFY_REQUIRED;

	/* List of security tags to register. */
	sec_tag_t sec_tag_list[] = {
		CA_CERTIFICATE_TAG,
		PSK_TAG,
	};

	sock = socket(AF_INET, SOCK_DGRAM, IPPROTO_DTLS_1_2);
	if (sock < 0) {
		LOG_ERR("Failed to create a DTLS socket. Err: %d", errno);
		return -errno;
	}

	err = setsockopt(sock, SOL_TLS, TLS_PEER_VERIFY, &verify, sizeof(verify));
	if (err < 0) {
		LOG_ERR("Failed to set DTLS peer verification. Err %d", errno);
		(void)close(sock);
		return -errno;
	}

	err = setsockopt(sock, SOL_TLS, TLS_SEC_TAG_LIST, sec_tag_list, sizeof(sec_tag_list));
	if (err < 0) {
		LOG_ERR("Failed to set DTLS security TAG list. Err: %d", errno);
		(void)close(sock);
		return -errno;
	}

	err = setsockopt(sock, SOL_TLS, TLS_HOSTNAME, TLS_PEER_HOSTNAME, sizeof(TLS_PEER_HOSTNAME));
	if (err < 0) {
		LOG_ERR("Failed to set TLS_HOSTNAME option. Err: %d", errno);
		(void)close(sock);
		return -errno;
	}

	int cache = TLS_SESSION_CACHE_ENABLED;

	err = setsockopt(sock, SOL_TLS, TLS_SESSION_CACHE, &cache, sizeof(cache));
	if (err < 0) {
		LOG_ERR("Failed to set TLS Session cache. Err: %d", errno);
		(void)close(sock);
		return -errno;
	}

	return sock;
}

/** @brief Function that handles all the steps of the DTLS handshake for
 *  a client. Loops forever and connects on given port number.
 *
 */
void process_psa_tls(void)
{
	int ret;
	int sock;
	int received = 0;
	bool connected;
	struct sockaddr_in server_addr;
	socklen_t server_addr_len = sizeof(server_addr);

	server_addr.sin_family = AF_INET;
	server_addr.sin_port = htons(CONFIG_SAMPLE_PSA_TLS_SERVER_PORT);
	inet_pton(AF_INET, CONFIG_NET_CONFIG_PEER_IPV4_ADDR, &server_addr.sin_addr);

	while (true) {
		connected = false;

		sock = setup_dtls_client_socket();
		if (sock < 0) {
			LOG_INF("Retrying acquiring socket");
			k_sleep(K_MSEC(1000));
			continue;
		}

		LOG_INF("Initiates DTLS connection on port %d ...",
			CONFIG_SAMPLE_PSA_TLS_SERVER_PORT);
		ret = connect(sock, (struct sockaddr *)&server_addr, server_addr_len);
		if (ret != 0) {
			LOG_WRN("Cannot make DTLS connection. Err: %d", errno);
			LOG_INF("Will re-try connection in 1 second");
			(void)close(sock);
			k_sleep(K_MSEC(1000));
			continue;
		}

		/* Send one byte to trigger handshake */
		ret = psa_tls_send_buffer(sock, recv_buffer, 1);
		if (ret != 0) {
			LOG_INF("Not connected yet. Will re-try initiating handshake in 1 second");
			(void)close(sock);
			k_sleep(K_MSEC(1000));
			continue;
		}

		while (!connected) {
			/* Try to receive data to confirm connection */
			received = recv(sock, recv_buffer, sizeof(recv_buffer), 0);

			if (received == 0) {
				/* Connection closed */
				LOG_INF("DTLS Connection closed");
				break;

			} else if (received < 0) {
				/* Not connected error is expected */
				if (errno == ENOTCONN || errno == EWOULDBLOCK) {
					LOG_INF("Not connected yet. Will re-try receive in 1 "
						"second");
					k_sleep(K_MSEC(1000));
					continue;
				}

				/* Socket error */
				LOG_ERR("DTLS Connection error: %d", errno);
				break;
			}

			connected = true;
			break;
		}

		if (connected) {
			LOG_INF("DTLS handshake completed");
			LOG_INF("DTLS received %d byte(s)", received);

			ret = psa_tls_send_buffer(sock, recv_buffer, received);
			if (ret != 0) {
				LOG_ERR("DTLS Failed to send. Err: %d", errno);
			} else {
				LOG_INF("DTLS replied with %d bytes", received);
				LOG_INF("Closing DTLS connection");
			}
		}

		(void)close(sock);
	}
}
```

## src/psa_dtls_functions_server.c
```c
/*
 * Copyright (c) 2023 Nordic Semiconductor ASA.
 *
 * SPDX-License-Identifier: LicenseRef-Nordic-5-Clause
 */

#include <errno.h>
#include <sys/socket.h>
#include <unistd.h>

#include <zephyr/logging/log.h>
#include <zephyr/net/tls_credentials.h>

#include <certificate.h>
#include <psa_tls_functions.h>
#include <psa_tls_credentials.h>

LOG_MODULE_REGISTER(psa_dtls_server);

static char recv_buffer[RECV_BUFFER_SIZE]; /* Buffer for storing payload */

/** @brief Function for setting up the server socket to use for DTLS handshake.
 *
 * @returns The socket identifier.
 */
static int setup_dtls_server_socket(void)
{
	int err;
	int sock;
	struct sockaddr_in my_addr;

	/* List of security tags to register. */
	sec_tag_t sec_tag_list[] = {
		SERVER_CERTIFICATE_TAG,
		PSK_TAG,
	};

	memset(&my_addr, 0, sizeof(my_addr));
	my_addr.sin_family = AF_INET;
	my_addr.sin_port = htons(CONFIG_SAMPLE_PSA_TLS_SERVER_PORT);

	sock = socket(my_addr.sin_family, SOCK_DGRAM, IPPROTO_DTLS_1_2);
	if (sock < 0) {
		LOG_ERR("Failed to create a DTLS socket. Err: %d", errno);
		return -errno;
	}

	err = setsockopt(sock, SOL_TLS, TLS_SEC_TAG_LIST, sec_tag_list, sizeof(sec_tag_list));
	if (err < 0) {
		LOG_ERR("Failed to set DTLS security TAG list. Err: %d", errno);
		(void)close(sock);
		return -errno;
	}

	int role = TLS_DTLS_ROLE_SERVER;

	err = setsockopt(sock, SOL_TLS, TLS_DTLS_ROLE, &role, sizeof(role));
	if (err < 0) {
		LOG_ERR("Failed to set DTLS role secure option: %d", errno);
		(void)close(sock);
		return -errno;
	}

	int cache = TLS_SESSION_CACHE_ENABLED;

	err = setsockopt(sock, SOL_TLS, TLS_SESSION_CACHE, &cache, sizeof(cache));
	if (err < 0) {
		LOG_ERR("Failed to set TLS Session cache. Err: %d", errno);
		(void)close(sock);
		return -errno;
	}

	err = bind(sock, (struct sockaddr *)&my_addr, sizeof(my_addr));
	if (err < 0) {
		LOG_ERR("Failed to bind DTLS socket. Err: %d", errno);
		(void)close(sock);
		return -errno;
	}

	return sock;
}

/** @brief Function that handles all the steps of the DTLS handshake for
 *  a server. Loops forever and accepts connections on the given port number.
 *
 */
void process_psa_tls(void)
{
	int ret;
	int client;
	int received = 0;
	struct sockaddr client_addr;
	socklen_t client_addr_len = sizeof(client_addr);

	while (true) {
		client = setup_dtls_server_socket();
		if (client < 0) {
			LOG_INF("Retrying to create a socket");
			k_sleep(K_MSEC(1000));
			continue;
		}

		LOG_INF("Waiting for DTLS connection on port %d ...",
			CONFIG_SAMPLE_PSA_TLS_SERVER_PORT);

		while (true) {
			/* Try to receive data while connected */
			received = recvfrom(client, recv_buffer, sizeof(recv_buffer), 0,
					    &client_addr, &client_addr_len);

			if (received == 0) {
				/* Connection closed */
				LOG_INF("DTLS Connection closed");
				break;

			} else if (received < 0) {
				/* Socket error */
				LOG_ERR("DTLS Connection error: %d", errno);
				break;
			}

			LOG_INF("DTLS received %d bytes", received);

			ret = psa_tls_send_buffer(client, recv_buffer, received);
			if (ret != 0) {
				LOG_ERR("DTLS Failed to send. Err: %d", errno);
				break;
			}

			LOG_INF("DTLS replied with %d bytes", received);
		}

		LOG_INF("Closing DTLS connection");
		(void)close(client);
	}
}
```

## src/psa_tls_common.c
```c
/*
 * Copyright (c) 2021 Nordic Semiconductor ASA.
 *
 * SPDX-License-Identifier: LicenseRef-Nordic-5-Clause
 */

#include <sys/socket.h>

/** @brief Function for sending all data in a given buffer to a connected
 * socket.
 *
 * @param   sock        The socket identifier to send data to.
 * @param   buf         Pointer to the data buffer.
 * @param   len         Number of bytes to send from buf.
 *
 * @returns 0 on success.
 */
int psa_tls_send_buffer(int sock, const uint8_t *buf, size_t len)
{
	ssize_t sent_len;

	while (len > 0) {
		sent_len = send(sock, buf, len, 0);
		if (sent_len < 0) {
			return -errno;
		}

		buf += sent_len;
		len -= sent_len;
	}

	return 0;
}
```

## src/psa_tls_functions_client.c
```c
/*
 * Copyright (c) 2021 Nordic Semiconductor ASA.
 *
 * SPDX-License-Identifier: LicenseRef-Nordic-5-Clause
 */

#include <arpa/inet.h>
#include <errno.h>
#include <sys/socket.h>
#include <unistd.h>

#include <zephyr/logging/log.h>
#include <zephyr/net/tls_credentials.h>

#include <certificate.h>
#include <psa_tls_functions.h>
#include <psa_tls_credentials.h>

LOG_MODULE_REGISTER(psa_tls_client);

static char recv_buffer[RECV_BUFFER_SIZE]; /* Buffer for storing payload */

/** @brief Function for setting up the client socket to use for TLS handshake.
 *
 * @returns The socket identifier.
 */
static int setup_tls_client_socket(void)
{
	int err;
	int sock;
	int verify = TLS_PEER_VERIFY_REQUIRED;

	/* List of security tags to register. */
	sec_tag_t sec_tag_list[] = {
		CA_CERTIFICATE_TAG,
		PSK_TAG,
	};

#if defined(CONFIG_MBEDTLS_TLS_VERSION_1_3)
	sock = socket(AF_INET, SOCK_STREAM, IPPROTO_TLS_1_3);
#else
	sock = socket(AF_INET, SOCK_STREAM, IPPROTO_TLS_1_2);
#endif
	if (sock < 0) {
		LOG_ERR("Failed to create a socket. Err: %d", errno);
		return -errno;
	}

	err = setsockopt(sock, SOL_TLS, TLS_PEER_VERIFY, &verify, sizeof(verify));
	if (err < 0) {
		LOG_ERR("Failed to set TLS peer verification. Err %d", errno);
		(void)close(sock);
		return -errno;
	}

	err = setsockopt(sock, SOL_TLS, TLS_SEC_TAG_LIST, sec_tag_list, sizeof(sec_tag_list));
	if (err < 0) {
		LOG_ERR("Failed to set TLS security TAG list. Err: %d", errno);
		(void)close(sock);
		return -errno;
	}

	err = setsockopt(sock, SOL_TLS, TLS_HOSTNAME, TLS_PEER_HOSTNAME, sizeof(TLS_PEER_HOSTNAME));
	if (err < 0) {
		LOG_ERR("Failed to set TLS_HOSTNAME option. Err: %d", errno);
		(void)close(sock);
		return -errno;
	}

	int cache = TLS_SESSION_CACHE_ENABLED;

	err = setsockopt(sock, SOL_TLS, TLS_SESSION_CACHE, &cache, sizeof(cache));
	if (err < 0) {
		LOG_ERR("Failed to set TLS Session cache. Err: %d", errno);
		(void)close(sock);
		return -errno;
	}

	return sock;
}

/** @brief Thread function that handles all the steps of the TLS handshake for
 *  a client. Loops forever and connects on given port number.
 *
 */
void process_psa_tls(void)
{
	int ret;
	int sock;
	int received;
	struct sockaddr_in server_addr;
	socklen_t server_addr_len = sizeof(server_addr);

	server_addr.sin_family = AF_INET;
	server_addr.sin_port = htons(CONFIG_SAMPLE_PSA_TLS_SERVER_PORT);
	inet_pton(AF_INET, CONFIG_NET_CONFIG_PEER_IPV4_ADDR, &server_addr.sin_addr);

	while (true) {

		sock = setup_tls_client_socket();
		if (sock < 0) {
			LOG_INF("Retrying acquiring socket");
			k_sleep(K_MSEC(1000));
			continue;
		}

		LOG_INF("Initiates TLS connection on port %d ...",
			CONFIG_SAMPLE_PSA_TLS_SERVER_PORT);
		ret = connect(sock, (struct sockaddr *)&server_addr, server_addr_len);

		if (ret < 0) {
			LOG_WRN("Cannot make TLS connection. Err: %d", errno);
			LOG_INF("Will re-try connection in 1 second");
			(void)close(sock);
			k_sleep(K_MSEC(1000));
			continue;
		}
		LOG_INF("TLS handshake completed");

		while (true) {
			/* Try to receive data while connected */
			received = recv(sock, recv_buffer, sizeof(recv_buffer), 0);

			if (received == 0) {
				/* Connection closed */
				LOG_INF("TLS Connection closed");
				break;

			} else if (received < 0) {
				/* Socket error */
				LOG_ERR("TLS Connection error: %d", errno);
				break;
			}

			LOG_INF("TLS received %d byte(s)", received);

			ret = psa_tls_send_buffer(sock, recv_buffer, received);
			if (ret != 0) {
				LOG_ERR("TLS Failed to send. Err: %d", errno);
				break;
			}

			LOG_INF("TLS replied with %d bytes", received);
		}

		LOG_INF("Closing TLS connection");
		(void)close(sock);
	}
}
```
